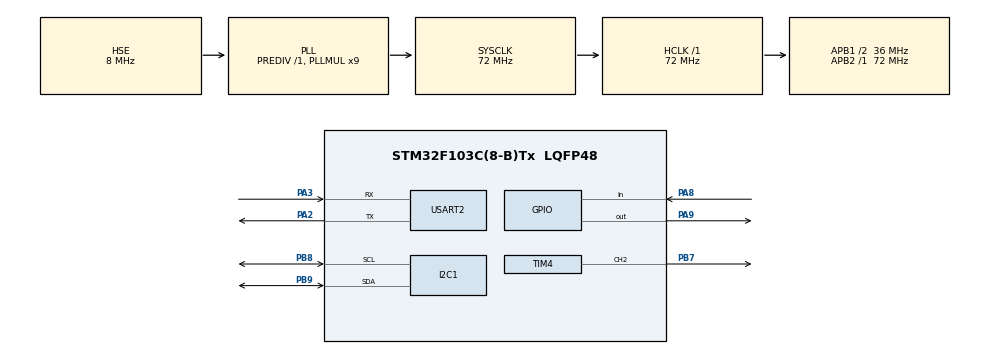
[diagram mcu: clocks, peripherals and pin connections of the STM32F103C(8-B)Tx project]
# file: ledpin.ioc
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Mcu.Family=STM32F1
Mcu.Name=STM32F103C(8-B)Tx
Mcu.Package=LQFP48
NVIC.I2C1_ER_IRQn=true\:0\:0\:false\:false\:true\:true\:true\:true
NVIC.I2C1_EV_IRQn=true\:0\:0\:false\:false\:true\:true\:true\:true
NVIC.PriorityGroup=NVIC_PRIORITYGROUP_4
NVIC.RCC_IRQn=true\:0\:0\:false\:false\:true\:true\:false\:true
NVIC.USART2_IRQn=true\:0\:0\:false\:false\:true\:true\:true\:true
PA13.Mode=Serial_Wire
PA13.Signal=SYS_JTMS-SWDIO
PA14.Mode=Serial_Wire
PA14.Signal=SYS_JTCK-SWCLK
PA2.Mode=Asynchronous
PA2.Signal=USART2_TX
PA3.Mode=Asynchronous
PA3.Signal=USART2_RX
PA8.Signal=GPIO_Input
PA9.Signal=GPIO_Output
PB7.Signal=S_TIM4_CH2
PB8.Mode=I2C
PB8.Signal=I2C1_SCL
PB9.Mode=I2C
PB9.Signal=I2C1_SDA
PD0-OSC_IN.Mode=HSE-External-Oscillator
PD0-OSC_IN.Signal=RCC_OSC_IN
PD1-OSC_OUT.Mode=HSE-External-Oscillator
PD1-OSC_OUT.Signal=RCC_OSC_OUT
ProjectManager.HeapSize=0x200
ProjectManager.StackSize=0x400
ProjectManager.TargetToolchain=MDK-ARM V5.32
RCC.AHBFreq_Value=72000000
RCC.APB1CLKDivider=RCC_HCLK_DIV2
RCC.APB1Freq_Value=36000000
RCC.APB1TimFreq_Value=72000000
RCC.APB2Freq_Value=72000000
RCC.APB2TimFreq_Value=72000000
RCC.HCLKFreq_Value=72000000
RCC.PLLMUL=RCC_PLL_MUL9
RCC.PLLSourceVirtual=RCC_PLLSOURCE_HSE
RCC.SYSCLKFreq_VALUE=72000000
RCC.SYSCLKSource=RCC_SYSCLKSOURCE_PLLCLK
RCC.USBFreq_Value=72000000
SH.S_TIM4_CH2.0=TIM4_CH2,PWM Generation2 CH2
TIM1.Period=0xffff-1
TIM1.Prescaler=71
TIM4.Channel-PWM\ Generation2\ CH2=TIM_CHANNEL_2
TIM4.Period=1000
TIM4.Prescaler=71
TIM4.Pulse-PWM\ Generation2\ CH2=500
USART2.VirtualMode=VM_ASYNC
VP_TIM1_VS_ClockSourceINT.Mode=Internal
VP_TIM4_VS_ClockSourceINT.Mode=Internal
board=custom

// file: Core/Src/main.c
/* USER CODE BEGIN Header */
/**
  ******************************************************************************
  * @file           : main.c
  * @brief          : Main program body
  ******************************************************************************
  * @attention
  *
  * Copyright (c) 2022 STMicroelectronics.
  * All rights reserved.
  *
  * This software is licensed under terms that can be found in the LICENSE file
  * in the root directory of this software component.
  * If no LICENSE file comes with this software, it is provided AS-IS.
  *
  ******************************************************************************
  */
/* USER CODE END Header */
#include "main.h"
#include "stdio.h"
#include "i2c-lcd.h"
#include "stdlib.h"

I2C_HandleTypeDef hi2c1;

TIM_HandleTypeDef htim1;
TIM_HandleTypeDef htim4;

UART_HandleTypeDef huart2;

/* USER CODE BEGIN PV */
#define TRIG_PIN GPIO_PIN_9
#define TRIG_PORT GPIOA
#define ECHO_PIN GPIO_PIN_8
#define ECHO_PORT GPIOA

uint32_t tempValue;
uint32_t val1 = 0;
uint32_t val2 = 0;
uint16_t distance  = 0;
char string[15];
/* USER CODE END PV */

void SystemClock_Config(void);
static void MX_GPIO_Init(void);
static void MX_I2C1_Init(void);
static void MX_USART2_UART_Init(void);
static void MX_TIM1_Init(void);
static void MX_TIM4_Init(void);

int main(void)
{

  /* MCU Configuration--------------------------------------------------------*/

  /* Reset of all peripherals, Initializes the Flash interface and the Systick. */
  HAL_Init();

  /* Configure the system clock */
  SystemClock_Config();

  /* Initialize all configured peripherals */
  MX_GPIO_Init();
  MX_I2C1_Init();
  MX_USART2_UART_Init();
  MX_TIM1_Init();
  MX_TIM4_Init();
	HAL_TIM_Base_Start(&htim1);
  HAL_GPIO_WritePin(TRIG_PORT, TRIG_PIN, GPIO_PIN_RESET);
	HAL_TIM_PWM_Start(&htim4, TIM_CHANNEL_2);

  /* USER CODE END 2 */
lcd_init();
lcd_send_string("TESTTTT");
HAL_Delay(5000);
  /* Infinite loop */
  /* USER CODE BEGIN WHILE */
  while (1)
  {
		lcd_clear();
		lcd_put_cur(0,0);
		HAL_GPIO_WritePin(TRIG_PORT, TRIG_PIN, GPIO_PIN_SET);
	  __HAL_TIM_SET_COUNTER(&htim1, 0);
	   while (__HAL_TIM_GET_COUNTER (&htim1) < 10);  // wait for 10 us
	   HAL_GPIO_WritePin(TRIG_PORT, TRIG_PIN, GPIO_PIN_RESET);

	   tempValue = HAL_GetTick();
	   while (!(HAL_GPIO_ReadPin (ECHO_PORT, ECHO_PIN)) && tempValue + 10 >  HAL_GetTick());
	   val1 = __HAL_TIM_GET_COUNTER (&htim1);

	   tempValue = HAL_GetTick();
	   while ((HAL_GPIO_ReadPin (ECHO_PORT, ECHO_PIN)) && tempValue + 50 > HAL_GetTick());
	   val2 = __HAL_TIM_GET_COUNTER (&htim1);

	   distance = (val2-val1)* 0.034/2;

		sprintf(string,"%d", distance);
	lcd_send_string(string);

		double dDistance = atof(string);
			if(dDistance > 60){
			htim4.Instance->CCR2 = 150;
			}
			else if (dDistance <60 && dDistance >30){
				htim4.Instance->CCR2 = 90;
			}
			else if (dDistance <30 && dDistance >15){
				htim4.Instance->CCR2 = 60;
			}
			else {
			htim4.Instance->CCR2 = 40;
			}

		 HAL_Delay(1000);
			lcd_clear();
  }
}

void SystemClock_Config(void)
{
  RCC_OscInitTypeDef RCC_OscInitStruct = {0};
  RCC_ClkInitTypeDef RCC_ClkInitStruct = {0};

  /** Initializes the RCC Oscillators according to the specified parameters
  * in the RCC_OscInitTypeDef structure.
  */
  RCC_OscInitStruct.OscillatorType = RCC_OSCILLATORTYPE_HSE;
  RCC_OscInitStruct.HSEState = RCC_HSE_ON;
  RCC_OscInitStruct.HSEPredivValue = RCC_HSE_PREDIV_DIV1;
  RCC_OscInitStruct.HSIState = RCC_HSI_ON;
  RCC_OscInitStruct.PLL.PLLState = RCC_PLL_ON;
  RCC_OscInitStruct.PLL.PLLSource = RCC_PLLSOURCE_HSE;
  RCC_OscInitStruct.PLL.PLLMUL = RCC_PLL_MUL9;
  if (HAL_RCC_OscConfig(&RCC_OscInitStruct) != HAL_OK)
  {
    Error_Handler();
  }

  /** Initializes the CPU, AHB and APB buses clocks
  */
  RCC_ClkInitStruct.ClockType = RCC_CLOCKTYPE_HCLK|RCC_CLOCKTYPE_SYSCLK
                              |RCC_CLOCKTYPE_PCLK1|RCC_CLOCKTYPE_PCLK2;
  RCC_ClkInitStruct.SYSCLKSource = RCC_SYSCLKSOURCE_PLLCLK;
  RCC_ClkInitStruct.AHBCLKDivider = RCC_SYSCLK_DIV1;
  RCC_ClkInitStruct.APB1CLKDivider = RCC_HCLK_DIV2;
  RCC_ClkInitStruct.APB2CLKDivider = RCC_HCLK_DIV1;

  if (HAL_RCC_ClockConfig(&RCC_ClkInitStruct, FLASH_LATENCY_2) != HAL_OK)
  {
    Error_Handler();
  }
}

static void MX_I2C1_Init(void)
{

  hi2c1.Instance = I2C1;
  hi2c1.Init.ClockSpeed = 100000;
  hi2c1.Init.DutyCycle = I2C_DUTYCYCLE_2;
  hi2c1.Init.OwnAddress1 = 0;
  hi2c1.Init.AddressingMode = I2C_ADDRESSINGMODE_7BIT;
  hi2c1.Init.DualAddressMode = I2C_DUALADDRESS_DISABLE;
  hi2c1.Init.OwnAddress2 = 0;
  hi2c1.Init.GeneralCallMode = I2C_GENERALCALL_DISABLE;
  hi2c1.Init.NoStretchMode = I2C_NOSTRETCH_DISABLE;
  if (HAL_I2C_Init(&hi2c1) != HAL_OK)
  {
    Error_Handler();
  }

}

static void MX_TIM1_Init(void)
{

  TIM_ClockConfigTypeDef sClockSourceConfig = {0};
  TIM_MasterConfigTypeDef sMasterConfig = {0};

  htim1.Instance = TIM1;
  htim1.Init.Prescaler = 71;
  htim1.Init.CounterMode = TIM_COUNTERMODE_UP;
  htim1.Init.Period = 0xffff-1;
  htim1.Init.ClockDivision = TIM_CLOCKDIVISION_DIV1;
  htim1.Init.RepetitionCounter = 0;
  htim1.Init.AutoReloadPreload = TIM_AUTORELOAD_PRELOAD_DISABLE;
  if (HAL_TIM_Base_Init(&htim1) != HAL_OK)
  {
    Error_Handler();
  }
  sClockSourceConfig.ClockSource = TIM_CLOCKSOURCE_INTERNAL;
  if (HAL_TIM_ConfigClockSource(&htim1, &sClockSourceConfig) != HAL_OK)
  {
    Error_Handler();
  }
  sMasterConfig.MasterOutputTrigger = TIM_TRGO_RESET;
  sMasterConfig.MasterSlaveMode = TIM_MASTERSLAVEMODE_DISABLE;
  if (HAL_TIMEx_MasterConfigSynchronization(&htim1, &sMasterConfig) != HAL_OK)
  {
    Error_Handler();
  }

}

static void MX_TIM4_Init(void)
{

  TIM_ClockConfigTypeDef sClockSourceConfig = {0};
  TIM_MasterConfigTypeDef sMasterConfig = {0};
  TIM_OC_InitTypeDef sConfigOC = {0};

  htim4.Instance = TIM4;
  htim4.Init.Prescaler = 720;
  htim4.Init.CounterMode = TIM_COUNTERMODE_UP;
  htim4.Init.Period = 1000;
  htim4.Init.ClockDivision = TIM_CLOCKDIVISION_DIV1;
  htim4.Init.AutoReloadPreload = TIM_AUTORELOAD_PRELOAD_DISABLE;
  if (HAL_TIM_Base_Init(&htim4) != HAL_OK)
  {
    Error_Handler();
  }
  sClockSourceConfig.ClockSource = TIM_CLOCKSOURCE_INTERNAL;
  if (HAL_TIM_ConfigClockSource(&htim4, &sClockSourceConfig) != HAL_OK)
  {
    Error_Handler();
  }
  if (HAL_TIM_PWM_Init(&htim4) != HAL_OK)
  {
    Error_Handler();
  }
  sMasterConfig.MasterOutputTrigger = TIM_TRGO_RESET;
  sMasterConfig.MasterSlaveMode = TIM_MASTERSLAVEMODE_DISABLE;
  if (HAL_TIMEx_MasterConfigSynchronization(&htim4, &sMasterConfig) != HAL_OK)
  {
    Error_Handler();
  }
  sConfigOC.OCMode = TIM_OCMODE_PWM1;
  sConfigOC.Pulse = 500;
  sConfigOC.OCPolarity = TIM_OCPOLARITY_HIGH;
  sConfigOC.OCFastMode = TIM_OCFAST_DISABLE;
  if (HAL_TIM_PWM_ConfigChannel(&htim4, &sConfigOC, TIM_CHANNEL_2) != HAL_OK)
  {
    Error_Handler();
  }
  HAL_TIM_MspPostInit(&htim4);

}

static void MX_USART2_UART_Init(void)
{

  huart2.Instance = USART2;
  huart2.Init.BaudRate = 115200;
  huart2.Init.WordLength = UART_WORDLENGTH_8B;
  huart2.Init.StopBits = UART_STOPBITS_1;
  huart2.Init.Parity = UART_PARITY_NONE;
  huart2.Init.Mode = UART_MODE_TX_RX;
  huart2.Init.HwFlowCtl = UART_HWCONTROL_NONE;
  huart2.Init.OverSampling = UART_OVERSAMPLING_16;
  if (HAL_UART_Init(&huart2) != HAL_OK)
  {
    Error_Handler();
  }

}

static void MX_GPIO_Init(void)
{
  GPIO_InitTypeDef GPIO_InitStruct = {0};

  /* GPIO Ports Clock Enable */
  __HAL_RCC_GPIOD_CLK_ENABLE();
  __HAL_RCC_GPIOA_CLK_ENABLE();
  __HAL_RCC_GPIOB_CLK_ENABLE();

  /*Configure GPIO pin Output Level */
  HAL_GPIO_WritePin(GPIOA, GPIO_PIN_9, GPIO_PIN_RESET);

  /*Configure GPIO pin : PA8 */
  GPIO_InitStruct.Pin = GPIO_PIN_8;
  GPIO_InitStruct.Mode = GPIO_MODE_INPUT;
  GPIO_InitStruct.Pull = GPIO_NOPULL;
  HAL_GPIO_Init(GPIOA, &GPIO_InitStruct);

  /*Configure GPIO pin : PA9 */
  GPIO_InitStruct.Pin = GPIO_PIN_9;
  GPIO_InitStruct.Mode = GPIO_MODE_OUTPUT_PP;
  GPIO_InitStruct.Pull = GPIO_NOPULL;
  GPIO_InitStruct.Speed = GPIO_SPEED_FREQ_LOW;
  HAL_GPIO_Init(GPIOA, &GPIO_InitStruct);

}

void Error_Handler(void)
{
  __disable_irq();
  while (1)
  {
  }
}
